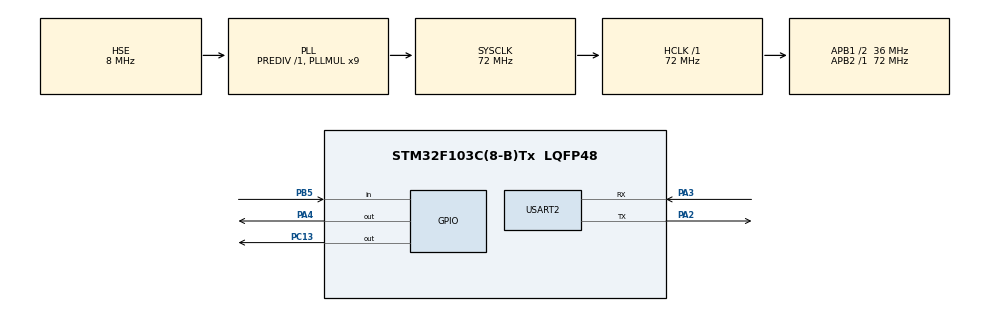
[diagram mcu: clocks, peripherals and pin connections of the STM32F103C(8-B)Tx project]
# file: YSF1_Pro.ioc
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FREERTOS.Tasks01=defaultTask,0,128,StartDefaultTask,Default,NULL,Dynamic,NULL,NULL;VTaskLED1,-1,128,vTaskLED1,Default,NULL,Dynamic,NULL,NULL
FREERTOS.configGENERATE_RUN_TIME_STATS=1
FREERTOS.configLIBRARY_MAX_SYSCALL_INTERRUPT_PRIORITY=1
FREERTOS.configTOTAL_HEAP_SIZE=17408
FREERTOS.configUSE_TRACE_FACILITY=1
Mcu.Family=STM32F1
Mcu.Name=STM32F103C(8-B)Tx
Mcu.Package=LQFP48
NVIC.PriorityGroup=NVIC_PRIORITYGROUP_4
NVIC.TIM1_UP_IRQn=true\:0\:0\:false\:false\:true\:false\:false
NVIC.TimeBase=TIM1_UP_IRQn
NVIC.TimeBaseIP=TIM1
PA13.Mode=Serial_Wire
PA13.Signal=SYS_JTMS-SWDIO
PA14.Mode=Serial_Wire
PA14.Signal=SYS_JTCK-SWCLK
PA2.Mode=Asynchronous
PA2.Signal=USART2_TX
PA3.Mode=Asynchronous
PA3.Signal=USART2_RX
PA4.Signal=GPIO_Output
PB5.Signal=GPIO_Input
PC13-TAMPER-RTC.Signal=GPIO_Output
PD0-OSC_IN.Mode=HSE-External-Oscillator
PD0-OSC_IN.Signal=RCC_OSC_IN
PD1-OSC_OUT.Mode=HSE-External-Oscillator
PD1-OSC_OUT.Signal=RCC_OSC_OUT
ProjectManager.HeapSize=0x200
ProjectManager.StackSize=0x400
ProjectManager.TargetToolchain=MDK-ARM V5
RCC.AHBFreq_Value=72000000
RCC.APB1CLKDivider=RCC_HCLK_DIV2
RCC.APB1Freq_Value=36000000
RCC.APB1TimFreq_Value=72000000
RCC.APB2Freq_Value=72000000
RCC.APB2TimFreq_Value=72000000
RCC.HCLKFreq_Value=72000000
RCC.PLLMUL=RCC_PLL_MUL9
RCC.PLLSourceVirtual=RCC_PLLSOURCE_HSE
RCC.SYSCLKFreq_VALUE=72000000
RCC.SYSCLKSource=RCC_SYSCLKSOURCE_PLLCLK
RCC.USBFreq_Value=72000000
USART2.VirtualMode=VM_ASYNC
VP_FREERTOS_VS_ENABLE.Mode=Enabled
VP_SYS_VS_tim1.Mode=TIM1
board=custom

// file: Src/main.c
/**
  ******************************************************************************
  * @file           : main.c
  * @brief          : Main program body
  ******************************************************************************
  * This notice applies to any and all portions of this file
  * that are not between comment pairs USER CODE BEGIN and
  * USER CODE END. Other portions of this file, whether
  * inserted by the user or by software development tools
  * are owned by their respective copyright owners.
  *
  * Copyright (c) 2018 STMicroelectronics International N.V.
  * All rights reserved.
  *
  * Redistribution and use in source and binary forms, with or without
  * modification, are permitted, provided that the following conditions are met:
  *
  * 1. Redistribution of source code must retain the above copyright notice,
  *    this list of conditions and the following disclaimer.
  * 2. Redistributions in binary form must reproduce the above copyright notice,
  *    this list of conditions and the following disclaimer in the documentation
  *    and/or other materials provided with the distribution.
  * 3. Neither the name of STMicroelectronics nor the names of other
  *    contributors to this software may be used to endorse or promote products
  *    derived from this software without specific written permission.
  * 4. This software, including modifications and/or derivative works of this
  *    software, must execute solely and exclusively on microcontroller or
  *    microprocessor devices manufactured by or for STMicroelectronics.
  * 5. Redistribution and use of this software other than as permitted under
  *    this license is void and will automatically terminate your rights under
  *    this license.
  *
  * THIS SOFTWARE IS PROVIDED BY STMICROELECTRONICS AND CONTRIBUTORS "AS IS"
  * AND ANY EXPRESS, IMPLIED OR STATUTORY WARRANTIES, INCLUDING, BUT NOT
  * LIMITED TO, THE IMPLIED WARRANTIES OF MERCHANTABILITY, FITNESS FOR A
  * PARTICULAR PURPOSE AND NON-INFRINGEMENT OF THIRD PARTY INTELLECTUAL PROPERTY
  * RIGHTS ARE DISCLAIMED TO THE FULLEST EXTENT PERMITTED BY LAW. IN NO EVENT
  * SHALL STMICROELECTRONICS OR CONTRIBUTORS BE LIABLE FOR ANY DIRECT, INDIRECT,
  * INCIDENTAL, SPECIAL, EXEMPLARY, OR CONSEQUENTIAL DAMAGES (INCLUDING, BUT NOT
  * LIMITED TO, PROCUREMENT OF SUBSTITUTE GOODS OR SERVICES; LOSS OF USE, DATA,
  * OR PROFITS; OR BUSINESS INTERRUPTION) HOWEVER CAUSED AND ON ANY THEORY OF
  * LIABILITY, WHETHER IN CONTRACT, STRICT LIABILITY, OR TORT (INCLUDING
  * NEGLIGENCE OR OTHERWISE) ARISING IN ANY WAY OUT OF THE USE OF THIS SOFTWARE,
  * EVEN IF ADVISED OF THE POSSIBILITY OF SUCH DAMAGE.
  *
  ******************************************************************************
  */
#include "main.h"
#include "stm32f1xx_hal.h"
#include "cmsis_os.h"
#include "usart.h"
#include "gpio.h"

/* USER CODE BEGIN PV */
/* Private variables ---------------------------------------------------------*/

/* USER CODE END PV */

void SystemClock_Config(void);
void MX_FREERTOS_Init(void);

/* USER CODE BEGIN PFP */
/* Private function prototypes -----------------------------------------------*/

/* USER CODE END PFP */

int main(void)
{

  /* MCU Configuration----------------------------------------------------------*/

  /* Reset of all peripherals, Initializes the Flash interface and the Systick. */
  HAL_Init();

  /* Configure the system clock */
  SystemClock_Config();

  /* Initialize all configured peripherals */
  MX_GPIO_Init();
  MX_USART2_UART_Init();

  /* Call init function for freertos objects (in freertos.c) */
  MX_FREERTOS_Init();

  /* Start scheduler */
  osKernelStart();

  /* We should never get here as control is now taken by the scheduler */

  /* Infinite loop */
  while (1)
  {

  }

}

void SystemClock_Config(void)
{

  RCC_OscInitTypeDef RCC_OscInitStruct;
  RCC_ClkInitTypeDef RCC_ClkInitStruct;

    /**Initializes the CPU, AHB and APB busses clocks
    */
  RCC_OscInitStruct.OscillatorType = RCC_OSCILLATORTYPE_HSE;
  RCC_OscInitStruct.HSEState = RCC_HSE_ON;
  RCC_OscInitStruct.HSEPredivValue = RCC_HSE_PREDIV_DIV1;
  RCC_OscInitStruct.HSIState = RCC_HSI_ON;
  RCC_OscInitStruct.PLL.PLLState = RCC_PLL_ON;
  RCC_OscInitStruct.PLL.PLLSource = RCC_PLLSOURCE_HSE;
  RCC_OscInitStruct.PLL.PLLMUL = RCC_PLL_MUL9;
  if (HAL_RCC_OscConfig(&RCC_OscInitStruct) != HAL_OK)
  {
    _Error_Handler(__FILE__, __LINE__);
  }

    /**Initializes the CPU, AHB and APB busses clocks
    */
  RCC_ClkInitStruct.ClockType = RCC_CLOCKTYPE_HCLK|RCC_CLOCKTYPE_SYSCLK
                              |RCC_CLOCKTYPE_PCLK1|RCC_CLOCKTYPE_PCLK2;
  RCC_ClkInitStruct.SYSCLKSource = RCC_SYSCLKSOURCE_PLLCLK;
  RCC_ClkInitStruct.AHBCLKDivider = RCC_SYSCLK_DIV1;
  RCC_ClkInitStruct.APB1CLKDivider = RCC_HCLK_DIV2;
  RCC_ClkInitStruct.APB2CLKDivider = RCC_HCLK_DIV1;

  if (HAL_RCC_ClockConfig(&RCC_ClkInitStruct, FLASH_LATENCY_2) != HAL_OK)
  {
    _Error_Handler(__FILE__, __LINE__);
  }

    /**Configure the Systick interrupt time
    */
  HAL_SYSTICK_Config(HAL_RCC_GetHCLKFreq()/1000);

    /**Configure the Systick
    */
  HAL_SYSTICK_CLKSourceConfig(SYSTICK_CLKSOURCE_HCLK);

  /* SysTick_IRQn interrupt configuration */
  HAL_NVIC_SetPriority(SysTick_IRQn, 15, 0);
}

void HAL_TIM_PeriodElapsedCallback(TIM_HandleTypeDef *htim)
{
  if (htim->Instance == TIM1) {
    HAL_IncTick();
  }
}

void _Error_Handler(char *file, int line)
{
  while(1)
  {
  }
}

/************************ (C) COPYRIGHT STMicroelectronics *****END OF FILE****/

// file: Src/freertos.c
/**
  ******************************************************************************
  * File Name          : freertos.c
  * Description        : Code for freertos applications
  ******************************************************************************
  * This notice applies to any and all portions of this file
  * that are not between comment pairs USER CODE BEGIN and
  * USER CODE END. Other portions of this file, whether
  * inserted by the user or by software development tools
  * are owned by their respective copyright owners.
  *
  * Copyright (c) 2018 STMicroelectronics International N.V.
  * All rights reserved.
  *
  * Redistribution and use in source and binary forms, with or without
  * modification, are permitted, provided that the following conditions are met:
  *
  * 1. Redistribution of source code must retain the above copyright notice,
  *    this list of conditions and the following disclaimer.
  * 2. Redistributions in binary form must reproduce the above copyright notice,
  *    this list of conditions and the following disclaimer in the documentation
  *    and/or other materials provided with the distribution.
  * 3. Neither the name of STMicroelectronics nor the names of other
  *    contributors to this software may be used to endorse or promote products
  *    derived from this software without specific written permission.
  * 4. This software, including modifications and/or derivative works of this
  *    software, must execute solely and exclusively on microcontroller or
  *    microprocessor devices manufactured by or for STMicroelectronics.
  * 5. Redistribution and use of this software other than as permitted under
  *    this license is void and will automatically terminate your rights under
  *    this license.
  *
  * THIS SOFTWARE IS PROVIDED BY STMICROELECTRONICS AND CONTRIBUTORS "AS IS"
  * AND ANY EXPRESS, IMPLIED OR STATUTORY WARRANTIES, INCLUDING, BUT NOT
  * LIMITED TO, THE IMPLIED WARRANTIES OF MERCHANTABILITY, FITNESS FOR A
  * PARTICULAR PURPOSE AND NON-INFRINGEMENT OF THIRD PARTY INTELLECTUAL PROPERTY
  * RIGHTS ARE DISCLAIMED TO THE FULLEST EXTENT PERMITTED BY LAW. IN NO EVENT
  * SHALL STMICROELECTRONICS OR CONTRIBUTORS BE LIABLE FOR ANY DIRECT, INDIRECT,
  * INCIDENTAL, SPECIAL, EXEMPLARY, OR CONSEQUENTIAL DAMAGES (INCLUDING, BUT NOT
  * LIMITED TO, PROCUREMENT OF SUBSTITUTE GOODS OR SERVICES; LOSS OF USE, DATA,
  * OR PROFITS; OR BUSINESS INTERRUPTION) HOWEVER CAUSED AND ON ANY THEORY OF
  * LIABILITY, WHETHER IN CONTRACT, STRICT LIABILITY, OR TORT (INCLUDING
  * NEGLIGENCE OR OTHERWISE) ARISING IN ANY WAY OUT OF THE USE OF THIS SOFTWARE,
  * EVEN IF ADVISED OF THE POSSIBILITY OF SUCH DAMAGE.
  *
  ******************************************************************************
  */

#include "FreeRTOS.h"
#include "task.h"
#include "cmsis_os.h"

/* USER CODE BEGIN Includes */
#include "bsp/led/bsp_led.h"
//#include "bsp/usart/bsp_debug_usart.h"
#include "bsp/key/bsp_key.h"
//#include "bsp/BasicTIM/bsp_BasicTIM.h"

/* USER CODE END Includes */

osThreadId defaultTaskHandle;
osThreadId VTaskLED1Handle;

/* USER CODE BEGIN Variables */
extern UART_HandleTypeDef huart2;
/* USER CODE END Variables */

void StartDefaultTask(void const * argument);
void vTaskLED1(void const * argument);

void MX_FREERTOS_Init(void); /* (MISRA C 2004 rule 8.1) */

/* Hook prototypes */
void configureTimerForRunTimeStats(void);
unsigned long getRunTimeCounterValue(void);

/* USER CODE BEGIN 1 */
/* Functions needed when configGENERATE_RUN_TIME_STATS is on */
__weak void configureTimerForRunTimeStats(void)
{

}

__weak unsigned long getRunTimeCounterValue(void)
{
return 0;
}
/* USER CODE END 1 */

/* Init FreeRTOS */

void MX_FREERTOS_Init(void) {

  /* Create the thread(s) */
  /* definition and creation of defaultTask */
  osThreadDef(defaultTask, StartDefaultTask, osPriorityNormal, 0, 128);
  defaultTaskHandle = osThreadCreate(osThread(defaultTask), NULL);

  /* definition and creation of VTaskLED1 */
  osThreadDef(VTaskLED1, vTaskLED1, osPriorityBelowNormal, 0, 128);
  VTaskLED1Handle = osThreadCreate(osThread(VTaskLED1), NULL);

}

/* StartDefaultTask function */
void StartDefaultTask(void const * argument)
{

  /* USER CODE BEGIN StartDefaultTask */
  uint8_t pcWriteBuffer[16] = {0x13, 0x3, 0x1, 0x0, 0x0, 0x1, 0x86, 0x84};
  uint8_t pcReadBuffer[16];
  /* Infinite loop */
  for(;;)
  {
    if(KEY1_StateRead()==KEY_DOWN)
    {
			LED2_ON;
      HAL_UART_Transmit(&huart2, pcWriteBuffer, 8, 0xffff);
      osDelay(10);
			LED2_OFF;
      HAL_UART_Receive(&huart2, pcReadBuffer, 7, 15);
			pcReadBuffer[15] = 0;
    }
    osDelay(1);
  }
  /* USER CODE END StartDefaultTask */
}

/* vTaskLED1 function */
void vTaskLED1(void const * argument)
{
  /* USER CODE BEGIN vTaskLED1 */
  /* Infinite loop */
  for(;;)
  {
    LED1_TOGGLE;
    osDelay(100);
  }
  /* USER CODE END vTaskLED1 */
}

/************************ (C) COPYRIGHT STMicroelectronics *****END OF FILE****/
